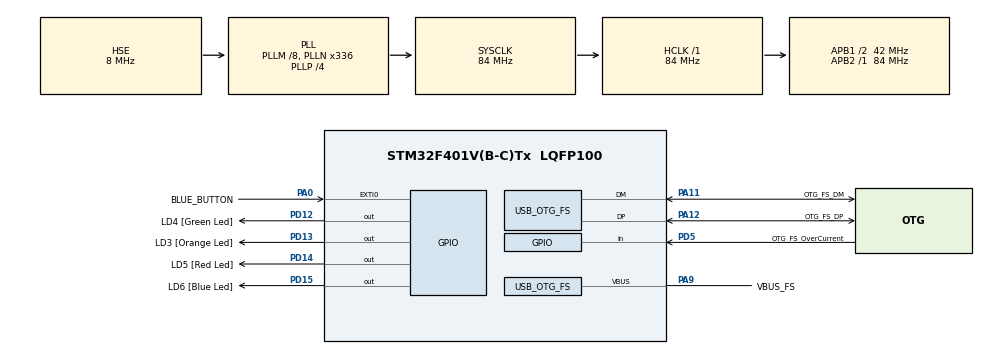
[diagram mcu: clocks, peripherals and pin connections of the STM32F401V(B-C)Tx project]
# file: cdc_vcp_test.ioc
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Mcu.Family=STM32F4
Mcu.Name=STM32F401V(B-C)Tx
Mcu.Package=LQFP100
NVIC.EXTI0_IRQn=true\:0\:2\:false\:false\:true\:true\:true
NVIC.OTG_FS_IRQn=true\:0\:1\:false\:false\:true\:true\:true
NVIC.PriorityGroup=NVIC_PRIORITYGROUP_0
PA0-WKUP.GPIO_Label=BLUE_BUTTON
PA0-WKUP.Signal=GPXTI0
PA10.GPIO_Label=OTG_FS_ID
PA10.Signal=USB_OTG_FS_ID
PA11.GPIO_Label=OTG_FS_DM
PA11.Mode=Device_Only
PA11.Signal=USB_OTG_FS_DM
PA12.GPIO_Label=OTG_FS_DP
PA12.Mode=Device_Only
PA12.Signal=USB_OTG_FS_DP
PA13.GPIO_Label=SWDIO
PA13.Mode=Serial_Wire
PA13.Signal=SYS_JTMS-SWDIO
PA14.GPIO_Label=SWCLK
PA14.Mode=Serial_Wire
PA14.Signal=SYS_JTCK-SWCLK
PA9.GPIO_Label=VBUS_FS
PA9.Mode=Activate_VBUS
PA9.Signal=USB_OTG_FS_VBUS
PC14-OSC32_IN.GPIO_Label=PC14-OSC32_IN
PC14-OSC32_IN.Mode=LSE-External-Oscillator
PC14-OSC32_IN.Signal=RCC_OSC32_IN
PC15-OSC32_OUT.GPIO_Label=PC15-OSC32_OUT
PC15-OSC32_OUT.Mode=LSE-External-Oscillator
PC15-OSC32_OUT.Signal=RCC_OSC32_OUT
PD12.GPIO_Label=LD4 [Green Led]
PD12.GPIO_PuPd=GPIO_NOPULL
PD12.GPIO_Speed=GPIO_SPEED_FREQ_LOW
PD12.Signal=GPIO_Output
PD13.GPIO_Label=LD3 [Orange Led]
PD13.GPIO_PuPd=GPIO_NOPULL
PD13.GPIO_Speed=GPIO_SPEED_FREQ_LOW
PD13.Signal=GPIO_Output
PD14.GPIO_Label=LD5 [Red Led]
PD14.GPIO_PuPd=GPIO_NOPULL
PD14.GPIO_Speed=GPIO_SPEED_FREQ_LOW
PD14.Signal=GPIO_Output
PD15.GPIO_Label=LD6 [Blue Led]
PD15.GPIO_PuPd=GPIO_NOPULL
PD15.GPIO_Speed=GPIO_SPEED_FREQ_LOW
PD15.Signal=GPIO_Output
PD5.GPIO_Label=OTG_FS_OverCurrent
PD5.Signal=GPIO_Input
PH0\ -\ OSC_IN.GPIO_Label=PH0-OSC_IN
PH0\ -\ OSC_IN.Mode=HSE-External-Oscillator
PH0\ -\ OSC_IN.Signal=RCC_OSC_IN
PH1\ -\ OSC_OUT.GPIO_Label=PH1-OSC_OUT
PH1\ -\ OSC_OUT.Mode=HSE-External-Oscillator
PH1\ -\ OSC_OUT.Signal=RCC_OSC_OUT
ProjectManager.HeapSize=0x200
ProjectManager.StackSize=0x400
ProjectManager.TargetToolchain=STM32CubeIDE
RCC.AHBFreq_Value=84000000
RCC.APB1CLKDivider=RCC_HCLK_DIV2
RCC.APB1Freq_Value=42000000
RCC.APB1TimFreq_Value=84000000
RCC.APB2Freq_Value=84000000
RCC.APB2TimFreq_Value=84000000
RCC.CortexFreq_Value=84000000
RCC.HCLKFreq_Value=84000000
RCC.HSE_VALUE=8000000
RCC.HSI_VALUE=16000000
RCC.PLLM=8
RCC.PLLN=336
RCC.PLLP=RCC_PLLP_DIV4
RCC.PLLQ=7
RCC.SYSCLKFreq_VALUE=84000000
RCC.SYSCLKSource=RCC_SYSCLKSOURCE_PLLCLK
RCC.VCOOutputFreq_Value=336000000
USB_DEVICE.APP_RX_DATA_SIZE=16
USB_DEVICE.APP_TX_DATA_SIZE=16
USB_DEVICE.CLASS_NAME_FS=CDC
USB_DEVICE.USBD_SELF_POWERED=0
USB_DEVICE.VirtualMode=Cdc
USB_DEVICE.VirtualModeFS=Cdc_FS
USB_OTG_FS.VirtualMode=Device_Only
VP_USB_DEVICE_VS_USB_DEVICE_CDC_FS.Mode=CDC_FS
board=STM32F401C-DISCO

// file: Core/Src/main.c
/* USER CODE BEGIN Header */
/**
  ******************************************************************************
  * @file           : main.c
  * @brief          : Main program body
  ******************************************************************************
  * @attention
  *
  * <h2><center>&copy; Copyright (c) 2021 STMicroelectronics.
  * All rights reserved.</center></h2>
  *
  * This software component is licensed by ST under Ultimate Liberty license
  * SLA0044, the "License"; You may not use this file except in compliance with
  * the License. You may obtain a copy of the License at:
  *                             www.st.com/SLA0044
  *
  ******************************************************************************
  */
/* USER CODE END Header */
#include "main.h"
#include "usb_device.h"
#include "gpio.h"

void SystemClock_Config(void);

int main(void)
{

  /* MCU Configuration--------------------------------------------------------*/

  /* Reset of all peripherals, Initializes the Flash interface and the Systick. */
  HAL_Init();

  /* Configure the system clock */
  SystemClock_Config();

  /* Initialize all configured peripherals */
  MX_GPIO_Init();
  MX_USB_DEVICE_Init();
  /* USER CODE BEGIN 2 */
  GPIO_FlashLedsOnStartUp();
  /* USER CODE END 2 */

  /* Infinite loop */
  /* USER CODE BEGIN WHILE */
  while (1)
  {
      OnBlueButtonPress();
      CDC_OnReceivedData();
    /* USER CODE END WHILE */

  }
}

void SystemClock_Config(void)
{
  RCC_OscInitTypeDef RCC_OscInitStruct = {0};
  RCC_ClkInitTypeDef RCC_ClkInitStruct = {0};

  /** Configure the main internal regulator output voltage
  */
  __HAL_RCC_PWR_CLK_ENABLE();
  __HAL_PWR_VOLTAGESCALING_CONFIG(PWR_REGULATOR_VOLTAGE_SCALE2);
  /** Initializes the RCC Oscillators according to the specified parameters
  * in the RCC_OscInitTypeDef structure.
  */
  RCC_OscInitStruct.OscillatorType = RCC_OSCILLATORTYPE_HSE;
  RCC_OscInitStruct.HSEState = RCC_HSE_ON;
  RCC_OscInitStruct.PLL.PLLState = RCC_PLL_ON;
  RCC_OscInitStruct.PLL.PLLSource = RCC_PLLSOURCE_HSE;
  RCC_OscInitStruct.PLL.PLLM = 8;
  RCC_OscInitStruct.PLL.PLLN = 336;
  RCC_OscInitStruct.PLL.PLLP = RCC_PLLP_DIV4;
  RCC_OscInitStruct.PLL.PLLQ = 7;
  if (HAL_RCC_OscConfig(&RCC_OscInitStruct) != HAL_OK)
  {
    Error_Handler();
  }
  /** Initializes the CPU, AHB and APB buses clocks
  */
  RCC_ClkInitStruct.ClockType = RCC_CLOCKTYPE_HCLK|RCC_CLOCKTYPE_SYSCLK
                              |RCC_CLOCKTYPE_PCLK1|RCC_CLOCKTYPE_PCLK2;
  RCC_ClkInitStruct.SYSCLKSource = RCC_SYSCLKSOURCE_PLLCLK;
  RCC_ClkInitStruct.AHBCLKDivider = RCC_SYSCLK_DIV1;
  RCC_ClkInitStruct.APB1CLKDivider = RCC_HCLK_DIV2;
  RCC_ClkInitStruct.APB2CLKDivider = RCC_HCLK_DIV1;

  if (HAL_RCC_ClockConfig(&RCC_ClkInitStruct, FLASH_LATENCY_2) != HAL_OK)
  {
    Error_Handler();
  }
}

void Error_Handler(void)
{
  __disable_irq();
  while (1)
  {
  }
}

/************************ (C) COPYRIGHT STMicroelectronics *****END OF FILE****/
